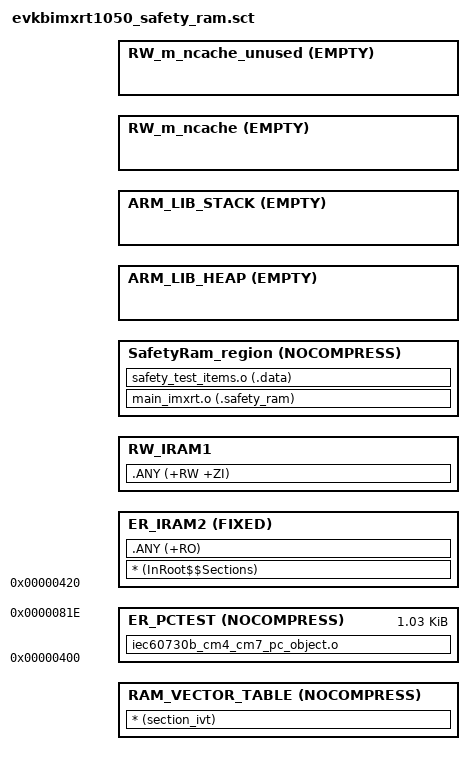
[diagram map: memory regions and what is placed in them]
#!armclang --target=arm-arm-none-eabi -mcpu=cortex-m7 -E -x c

/*
 * Copyright 2019 NXP.
 * All rights reserved.
 *
 * SPDX-License-Identifier: BSD-3-Clause
 */

 /*     
  *     Processors:          MIMXRT1052CVJ5B
  *                          MIMXRT1052CVL5B
  *                          MIMXRT1052DVJ6B
  *                          MIMXRT1052DVL6B
  */

/**********************************************************************************/
/****************************        MEMORY MAP        ****************************/
/**********************************************************************************/

/********************        FLASH        ********************/
//     __________________
//    |                  | --> 0x60000000 - ROM_start
//    |//// NOT USED ////|
//    |__________________| --> 0x63FFFFFF - ROM_end
//
//
/********************        SRAM        ********************/
//     __________________
//    |                  | --> 0x00000000 - RAM_interrupts_start
//    |       IVT        |
//    |__________________| --> 0x000003FF - RAM_interrupts_end 
//    |                  | --> 0x00000400 - SRAM_ITC_start
//    |     readonly     |
//    |__________________| --> 0x0001FFFF - SRAM_ITC_end 
//    |                  |
//    |//// RESERVED ////|
//    |__________________|
//    |                  | --> 0x20000000 - SRAM_DTC_start
//    |     RW (.data)   | --> copying in startup_iar.c
//    |     ZI (.bss)    | --> copying in startup_iar.c
//    | SAFETY_RAM_BLOCK | 
//    |__________________| --> SRAM_DTC_end_edited
//    |                  | --> m_stack_test_p_1
//    |                  |
//    |__________________| --> m_stack_test_p_2
//    |                  |
//    |                  |
//    |      STACK       |
//    |                  |
//    |__________________| --> __BOOT_STACK_ADDRESS
//    |                  | --> m_stack_test_p_3
//    |                  |
//    |__________________| --> m_stack_test_p_4
//    |__________________| --> m_safety_error_code
//    |__________________| --> m_pc_test_flag
//    |                  | --> m_wd_test_backup
//    |__________________|
//    |                  |
//    |                  | --> m_ram_test_backup
//    |__________________|
//    |__________________| --> 0x2001FFFF - SRAM_DTC_end
//    |                  |
//    |//// RESERVED ////|
//    |__________________|
//    |                  | --> 0x20200000 - SRAM_OC_start
//    |//// NOT USED ////|
//    |__________________| --> 0x2023FFFF - SRAM_OC_end
//
//
/********************        SDRAM        ********************/
//     __________________
//    |                  | --> 0x80000000 - SDRAM_start
//    |//// NOT USED ////|
//    |__________________| --> 0x81FFFFFF - SDRAM_end
//
//
 
; *************************************************************
; *** Scatter-Loading Description File                      ***
; *************************************************************
#include "linker_config.h"

LR_SRAM_ITC SRAM_ITC_start SRAM_ITC_end + 1 {   ; load region size_region
    RAM_VECTOR_TABLE SRAM_ITC_start NOCOMPRESS __vector_table_size__ {
        * (section_ivt)
	}
	
    /************ PC test object ************/
    ER_PCTEST 0x400 NOCOMPRESS 0x41F {
        iec60730b_cm4_cm7_pc_object.o 
    }
    /************ PC test object ************/
    
    ER_IRAM2 0x420 FIXED SRAM_ITC_end - 0x420 + 1 {
		* (InRoot$$Sections)
        .ANY (+RO)
	}
}

LR_SRAM_DTC SRAM_DTC_start SRAM_DTC_end - SRAM_DTC_start + 1 {   ; load region size_region
	RW_IRAM1 SRAM_DTC_start m_data_size {
		.ANY (+RW +ZI)
	}
	
	SafetyRam_region m_safety_ram_start NOCOMPRESS SAFETY_RAM_SIZE {
		main_imxrt.o (.safety_ram)
		safety_test_items.o (.data)
	}
	
    ARM_LIB_HEAP +0 EMPTY 0x0 {    ; Heap region growing up
    }

    ARM_LIB_STACK __BOOT_STACK_ADDRESS EMPTY -__size_cstack__{ ; Stack region growing down
    } 
    
    RW_m_ncache +0 EMPTY 0x0 { ; Empty region added for MPU configuration
    }
    
    RW_m_ncache_unused +0 EMPTY 0x0 { ; Empty region added for MPU configuration
    }
}
